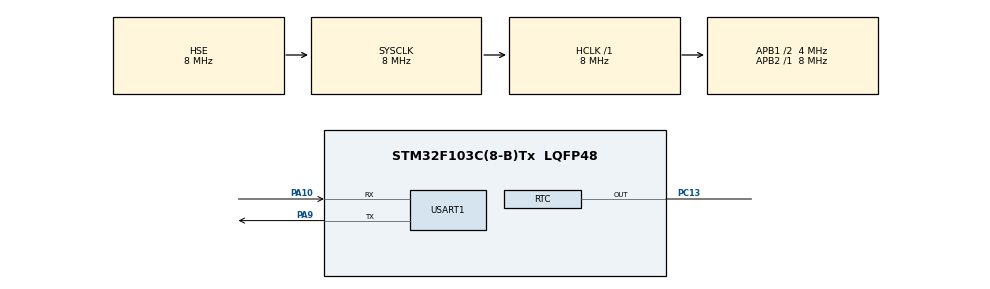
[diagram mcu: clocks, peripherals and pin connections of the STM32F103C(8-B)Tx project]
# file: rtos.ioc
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Mcu.Family=STM32F1
Mcu.Name=STM32F103C(8-B)Tx
Mcu.Package=LQFP48
NVIC.PriorityGroup=NVIC_PRIORITYGROUP_4
NVIC.RTC_Alarm_IRQn=true\:0\:0\:false\:false\:true\:true\:true
NVIC.RTC_IRQn=true\:0\:0\:false\:false\:true\:true\:true
PA10.Mode=Asynchronous
PA10.Signal=USART1_RX
PA13.Mode=Serial_Wire
PA13.Signal=SYS_JTMS-SWDIO
PA14.Mode=Serial_Wire
PA14.Signal=SYS_JTCK-SWCLK
PA9.Mode=Asynchronous
PA9.Signal=USART1_TX
PC13-TAMPER-RTC.Mode=RTC OUT
PC13-TAMPER-RTC.Signal=RTC_OUT
PD0-OSC_IN.Mode=HSE-External-Oscillator
PD0-OSC_IN.Signal=RCC_OSC_IN
PD1-OSC_OUT.Mode=HSE-External-Oscillator
PD1-OSC_OUT.Signal=RCC_OSC_OUT
ProjectManager.HeapSize=0x200
ProjectManager.StackSize=0x400
ProjectManager.TargetToolchain=STM32CubeIDE
RCC.AHBFreq_Value=8000000
RCC.APB1CLKDivider=RCC_HCLK_DIV2
RCC.APB1Freq_Value=4000000
RCC.APB1TimFreq_Value=8000000
RCC.APB2Freq_Value=8000000
RCC.APB2TimFreq_Value=8000000
RCC.HCLKFreq_Value=8000000
RCC.PLLMUL=RCC_PLL_MUL9
RCC.PLLSourceVirtual=RCC_PLLSOURCE_HSE
RCC.RTCClockSelection=RCC_RTCCLKSOURCE_HSE_DIV128
RCC.SYSCLKFreq_VALUE=8000000
RCC.SYSCLKSource=RCC_SYSCLKSOURCE_HSE
RCC.USBFreq_Value=72000000
USART1.VirtualMode=VM_ASYNC
VP_RTC_VS_RTC_Activate.Mode=RTC_Enabled
VP_RTC_VS_RTC_Calendar.Mode=RTC_Calendar
board=custom

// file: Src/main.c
/* USER CODE BEGIN Header */
/**
  ******************************************************************************
  * @file           : main.c
  * @brief          : Main program body
  ******************************************************************************
  * @attention
  *
  * <h2><center>&copy; Copyright (c) 2019 STMicroelectronics.
  * All rights reserved.</center></h2>
  *
  * This software component is licensed by ST under BSD 3-Clause license,
  * the "License"; You may not use this file except in compliance with the
  * License. You may obtain a copy of the License at:
  *                        opensource.org/licenses/BSD-3-Clause
  *
  ******************************************************************************
  */
/* USER CODE END Header */

#include "main.h"

RTC_HandleTypeDef hrtc;

UART_HandleTypeDef huart1;

void SystemClock_Config(void);
static void MX_GPIO_Init(void);
static void MX_RTC_Init(void);
static void MX_USART1_UART_Init(void);

/* USER CODE BEGIN 0 */

#ifdef __GNUC__
  /* With GCC/RAISONANCE, small printf (option LD Linker->Libraries->Small printf
     set to 'Yes') calls __io_putchar() */
  #define PUTCHAR_PROTOTYPE int __io_putchar(int ch)
#else
  #define PUTCHAR_PROTOTYPE int fputc(int ch, FILE *f)
#endif /* __GNUC__ */
PUTCHAR_PROTOTYPE
{
    /* Place your implementation of fputc here */
    /* e.g. write a character to the USART */
    HAL_UART_Transmit(&huart1, (uint8_t *)&ch, 1, 100);

    return ch;
}
void HAL_RTC_AlarmAEventCallback(RTC_HandleTypeDef *hrtc)
{
	__HAL_PWR_CLEAR_FLAG(PWR_FLAG_WU);
	  HAL_GPIO_TogglePin(GPIOC, GPIO_PIN_13);
	  char ch;
	  ch = '5';
	  HAL_UART_Transmit(&huart1,&ch,1, 100);
}

/* USER CODE END 0 */

int main(void)
{

  /* MCU Configuration--------------------------------------------------------*/

  /* Reset of all peripherals, Initializes the Flash interface and the Systick. */
  HAL_Init();

  /* Configure the system clock */
  SystemClock_Config();

  /* Initialize all configured peripherals */
  MX_GPIO_Init();
  MX_RTC_Init();
  MX_USART1_UART_Init();
  /* USER CODE BEGIN 2 */
  RTC_TimeTypeDef timeStruct;
  int hour, min, sec;

  //HAL_GPIO_TogglePin(GPIOC, GPIO_PIN_13);
  char ch;
  ch = '1';
  HAL_UART_Transmit(&huart1,&ch,1, 100);
  //HAL_PWR_EnterSTANDBYMode();
  /* USER CODE END 2 */

  /* Infinite loop */
  while (1)
  {

    /* USER CODE BEGIN 3 */
	  HAL_RTC_GetTime(&hrtc,&timeStruct,RTC_FORMAT_BIN);
      hour = timeStruct.Hours;
      min = timeStruct.Minutes;
      sec = timeStruct.Seconds;
  }
  /* USER CODE END 3 */
}

void SystemClock_Config(void)
{
  RCC_OscInitTypeDef RCC_OscInitStruct = {0};
  RCC_ClkInitTypeDef RCC_ClkInitStruct = {0};
  RCC_PeriphCLKInitTypeDef PeriphClkInit = {0};

  /** Initializes the CPU, AHB and APB busses clocks
  */
  RCC_OscInitStruct.OscillatorType = RCC_OSCILLATORTYPE_HSE;
  RCC_OscInitStruct.HSEState = RCC_HSE_ON;
  RCC_OscInitStruct.PLL.PLLState = RCC_PLL_NONE;
  if (HAL_RCC_OscConfig(&RCC_OscInitStruct) != HAL_OK)
  {
    Error_Handler();
  }
  /** Initializes the CPU, AHB and APB busses clocks
  */
  RCC_ClkInitStruct.ClockType = RCC_CLOCKTYPE_HCLK|RCC_CLOCKTYPE_SYSCLK
                              |RCC_CLOCKTYPE_PCLK1|RCC_CLOCKTYPE_PCLK2;
  RCC_ClkInitStruct.SYSCLKSource = RCC_SYSCLKSOURCE_HSE;
  RCC_ClkInitStruct.AHBCLKDivider = RCC_SYSCLK_DIV1;
  RCC_ClkInitStruct.APB1CLKDivider = RCC_HCLK_DIV2;
  RCC_ClkInitStruct.APB2CLKDivider = RCC_HCLK_DIV1;

  if (HAL_RCC_ClockConfig(&RCC_ClkInitStruct, FLASH_LATENCY_0) != HAL_OK)
  {
    Error_Handler();
  }
  PeriphClkInit.PeriphClockSelection = RCC_PERIPHCLK_RTC;
  PeriphClkInit.RTCClockSelection = RCC_RTCCLKSOURCE_HSE_DIV128;
  if (HAL_RCCEx_PeriphCLKConfig(&PeriphClkInit) != HAL_OK)
  {
    Error_Handler();
  }
}

static void MX_RTC_Init(void)
{

  RTC_TimeTypeDef sTime = {0};
  RTC_DateTypeDef DateToUpdate = {0};
  RTC_AlarmTypeDef sAlarm = {0};

  /** Initialize RTC Only
  */
  hrtc.Instance = RTC;
  hrtc.Init.AsynchPrediv = RTC_AUTO_1_SECOND;
  hrtc.Init.OutPut = RTC_OUTPUTSOURCE_ALARM;
  if (HAL_RTC_Init(&hrtc) != HAL_OK)
  {
    Error_Handler();
  }

  /** Initialize RTC and set the Time and Date
  */
  sTime.Hours = 0x0;
  sTime.Minutes = 0x0;
  sTime.Seconds = 0x0;

  if (HAL_RTC_SetTime(&hrtc, &sTime, RTC_FORMAT_BCD) != HAL_OK)
  {
    Error_Handler();
  }
  DateToUpdate.WeekDay = RTC_WEEKDAY_MONDAY;
  DateToUpdate.Month = RTC_MONTH_JANUARY;
  DateToUpdate.Date = 0x1;
  DateToUpdate.Year = 0x0;

  if (HAL_RTC_SetDate(&hrtc, &DateToUpdate, RTC_FORMAT_BCD) != HAL_OK)
  {
    Error_Handler();
  }
  /** Enable the Alarm A
  */
  sAlarm.AlarmTime.Hours = 0x0;
  sAlarm.AlarmTime.Minutes = 0x0;
  sAlarm.AlarmTime.Seconds = 0x5;
  sAlarm.Alarm = RTC_ALARM_A;
  if (HAL_RTC_SetAlarm_IT(&hrtc, &sAlarm, RTC_FORMAT_BCD) != HAL_OK)
  {
    Error_Handler();
  }

}

static void MX_USART1_UART_Init(void)
{

  huart1.Instance = USART1;
  huart1.Init.BaudRate = 115200;
  huart1.Init.WordLength = UART_WORDLENGTH_8B;
  huart1.Init.StopBits = UART_STOPBITS_1;
  huart1.Init.Parity = UART_PARITY_NONE;
  huart1.Init.Mode = UART_MODE_TX_RX;
  huart1.Init.HwFlowCtl = UART_HWCONTROL_NONE;
  huart1.Init.OverSampling = UART_OVERSAMPLING_16;
  if (HAL_UART_Init(&huart1) != HAL_OK)
  {
    Error_Handler();
  }

}

static void MX_GPIO_Init(void)
{

  /* GPIO Ports Clock Enable */
  __HAL_RCC_GPIOC_CLK_ENABLE();
  __HAL_RCC_GPIOD_CLK_ENABLE();
  __HAL_RCC_GPIOA_CLK_ENABLE();

}

void Error_Handler(void)
{
}

/************************ (C) COPYRIGHT STMicroelectronics *****END OF FILE****/
